# PIC32MK0512GPK064 device description
Architecture: MIPS; Family: PIC32MK; Series: PIC32MK
Registers are 32-bit, read-write, no defined reset value unless marked. A register's access mark holds for its fields unless they carry their own. Offsets are from the block's base; [hi:lo] are bit positions; {n}, {i} and the like mark numbered series.

## DSCTRL
Instances: DSCTRL 0x1f8c0200 in periph_pb6_std
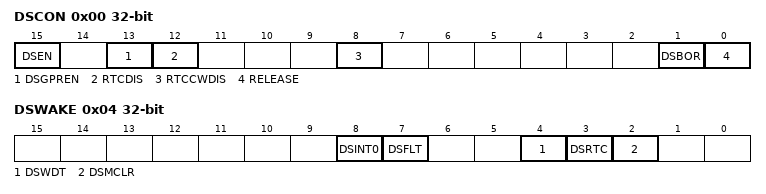
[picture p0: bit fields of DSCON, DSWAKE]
0x00 DSCON
  [15] DSEN — Deep Sleep Enable bit
    1=Deep Sleep mode is entered on a WAIT command; 0=Sleep mode is entered on a WAIT command
  [13] DSGPREN — General Purpose Registers Enable bit
    1=General purpose register retention is enabled in Deep Sleep mode; 0=No general purpose register retention in Deep Sleep mode
  [12] RTCDIS — RTCC Module Disable bit
    1=RTCC module is not enabled; 0=RTCC module is enabled
  [8] RTCCWDIS — RTCC Wake-up Disable bit
    1=Wake-up from RTCC is disabled; 0=Wake-up from RTCC is enabled
  [1] DSBOR — Deep Sleep BOR Event Status bit
    1=DSBOREN was enabled and VDD dropped below the DSBOR threshold during Deep Sleep; 0=DSBOREN was disabled, or VDD did not drop below the DSBOR threshold during Deep Sleep
  [0] RELEASE — I/O Pin State Release bit
    1=Upon waking from Deep Sleep, the I/O pins maintain their previous states; 0=Release I/O pins and allow their respective TRIS and LAT bits to control their states
0x04 DSWAKE
  [8] DSINT0 — Interrupt-on-Change bit
    1=Interrupt-on-change was asserted during Deep Sleep; 0=Interrupt-on-change was not asserted during Deep Sleep
  [7] DSFLT — Deep Sleep Fault Detected bit
    1=A Fault occurred during Deep Sleep and some Deep Sleep configuration settings may have been corrupted; 0=No Fault was detected during Deep Sleep
  [4] DSWDT — Deep Sleep Watchdog Timer Time-out bit
    1=The Deep Sleep Watchdog Timer timed out during Deep Sleep; 0=The Deep Sleep Watchdog Timer did not time-out during Deep Sleep
  [3] DSRTC — Real-Time Clock and Calendar Alarm bit
    1=The Real-Time Clock and Calendar triggered an alarm during Deep Sleep; 0=The Real-Time Clock and Calendar did not trigger an alarm during Deep Sleep
  [2] DSMCLR — MCLR Event bit
    1=The MCLR pin was active and was asserted during Deep Sleep; 0=The MCLR pin was not active, or was active, but not asserted during Deep Sleep
0x08 DSGPR0
  [31:0] DSGPR
{0xC+4i} DSGPR{i} (i=1..32)
  [31:0] DSGPR

## EEPROM
Instances: EEPROM 0x1f829000 in periph_pb2_std
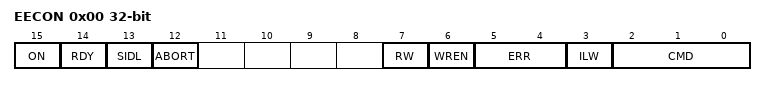
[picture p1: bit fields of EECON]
0x00 EECON — EEPROM Control Register
  [15] ON — Data EEPROM Power Control bit
    1=Data EEPROM is enabled; 0=Data EEPROM is disabled
  [14] RDY — Data EEPROM Ready bit
    1=Data EEPROM is ready for access; 0=Data EEPROM is not ready for access
  [13] SIDL — Stop in Idle Mode bit
    1=Discontinue operation when CPU enters in Idle mode; 0=Continue operation in Idle mode
  [12] ABORT — Data EEPROM Abort Operation Control bit
    1=Set by software to abort the on-going write command as soon as possible; 0=Data EEPROM panel is ready/Normal operation
  [7] RW — Start Command Execution Control bit
    1=(When WREN is 1)Start memory word program or erase command / (When WREN is 0)Start memory word read command; 0=(When WREN is 1)Cleared by hardware to indicate program or erase operation has completed / (When WREN is 0)Cleared by hardware to indicate read operation has completed
  [6] WREN — Data EEPROM Write Enable Control bit
    1=Enables program or erase operations; 0=Disables program or erase of memory elements, and enables read operations
  [5:4] ERR — Data EEPROM Sequence Error Status bits
    3=A BOR event has occurred; 2=An attempted execution of a read or write operation with an invalid write OR command with a misaligned address; 1=A Bulk or Page Erase or a Word Program verify error has occurred; 0=No error condition
  [3] ILW — Data EEPROM Imminent Long Write Status bit
    1=The next write to the EEPROM address (held in the EEADDR register) will require more time (~ 20 ms) than usual; 0=The next write to the EEPROM address (held in the EEADDR register) will be a normal write cycle
  [2:0] CMD — Data EEPROM Command Selection bits
    4=Configuration register Write command (WREN bit must be set); 3=Data EEPROM memory Bulk Erase command (WREN bit must be set); 2=Data EEPROM memory Page Erase command (WREN bit must be set); 1=Word Write command (WREN bit must be set); 0=Word Read command (WREN bit must be clear)
0x10 EEKEY wo
  [15:0] EEKEY
0x20 EEADDR
  [13:0] EEADDR
0x30 EEDATA

## Notices in the file
Copyright (c) 2019 Microchip Technology Inc.
SPDX-License-Identifier: Apache-2.0
Licensed under the Apache License, Version 2.0 (the "License");
you may not use this file except in compliance with the License.
You may obtain a copy of the License at
http://www.apache.org/licenses/LICENSE-2.0
Unless required by applicable law or agreed to in writing, software
distributed under the License is distributed on an "AS IS" BASIS,
WITHOUT WARRANTIES OR CONDITIONS OF ANY KIND, either express or implied.
See the License for the specific language governing permissions and
limitations under the License.
